# AT32F457xx_v2 register map
Vendor: Keil; Series: AT32F457; File version: 1.0
CPU: CM4 r0p1, little endian, no MPU, FPU, 4 interrupt priority bits
Registers are 32-bit, read-write, reset 0x0 unless marked. A register's access mark holds for its fields unless they carry their own. Offsets are from the block's base; [hi:lo] are bit positions.

## ETHERNET_DMA — Ethernet: DMA controller operation
Base 0x40029000
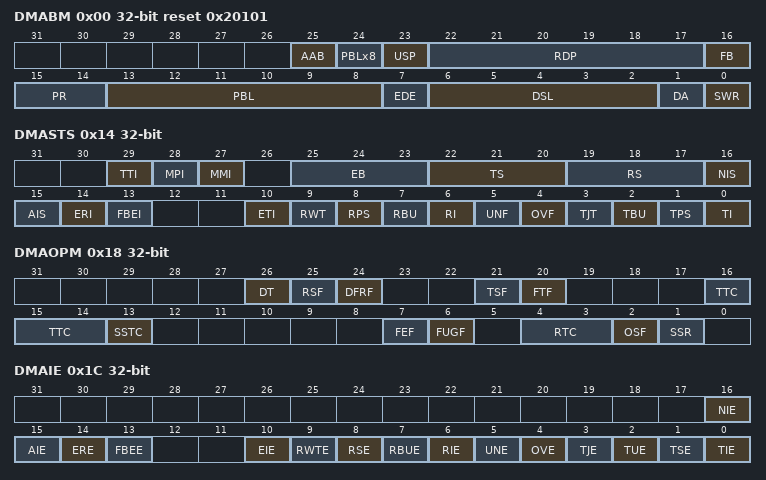
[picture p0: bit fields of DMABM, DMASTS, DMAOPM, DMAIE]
0x00 DMABM reset 0x20101 — Ethernet DMA bus mode register
  [25] AAB — Address-aligned beats
  [24] PBLx8 — PNLx8 mode
  [23] USP — Use separate PBL
  [22:17] RDP — Rx DMA PBL
  [16] FB — Fixed burst
  [15:14] PR — Priority ratio
  [13:8] PBL — Programmable burst length
  [7] EDE — Enhanced descriptor enable
  [6:2] DSL — Descriptor skip length
  [1] DA — DMA Arbitration
  [0] SWR — Software reset
0x04 DMATPD — Ethernet DMA transmit poll demand register
  [31:0] TPD — Transmit poll demand
0x08 DMARPD — EHERNET DMA receive poll demand register
  [31:0] RPD — Receive poll demand
0x0C DMARDLADDR — Ethernet DMA receive descriptor list address register
  [31:0] SRL — Start of receive list
0x10 DMATDLADDR — Ethernet DMA transmit descriptor list address register
  [31:0] STL — Start of transmit list
0x14 DMASTS — Ethernet DMA status register
  [29] TTI ro — Timestamp trigger interrupt
  [28] MPI ro — MAC PMT interrupt
  [27] MMI ro — MAC MMC interrupt
  [25:23] EB ro — Error bits
  [22:20] TS ro — Transmit process state
  [19:17] RS ro — Receive process state
  [16] NIS — Normal interrupt summary
  [15] AIS — Abnormal interrupt summary
  [14] ERI — Early receive interrupt
  [13] FBEI — Fatal bus error interrupt
  [10] ETI — Early transmit interrupt
  [9] RWT — Receive watchdog timeout
  [8] RPS — Receive process stopped
  [7] RBU — Receive buffer unavailable
  [6] RI — Receive interrupt
  [5] UNF — Transmit underflow
  [4] OVF — Receive overflow
  [3] TJT — Transmit jabber timeout
  [2] TBU — Transmit buffer unavailable
  [1] TPS — Transmit process stopped
  [0] TI — Transmit interrupt
0x18 DMAOPM — Ethernet DMA operation mode register
  [26] DT — Disable dropping of TCP/IP checksum error frames
  [25] RSF — Receive store and forward
  [24] DFRF — Disable flushing of received frames
  [21] TSF — Transmit store and forward
  [20] FTF — Flush transmit FIFO
  [16:14] TTC — Transmit threshold control
  [13] SSTC — Start of stop transmission command
  [7] FEF — Forward error frames
  [6] FUGF — Forward undersized good frames
  [4:3] RTC — Receive threshold control
  [2] OSF — Operate on second frame
  [1] SSR — Start or stop receive
0x1C DMAIE — Ethernet DMA interrupt enable register
  [16] NIE — Normal interrupt enable
  [15] AIE — Abnormal interrupt enable
  [14] ERE — Early receive interrupt enable
  [13] FBEE — Fatal bus error enable
  [10] EIE — Early transmit interrupt enable
  [9] RWTE — receive watchdog timeout enable
  [8] RSE — Receive stopped enable
  [7] RBUE — Receive buffer unavailable enable
  [6] RIE — Receive interrupt enable
  [5] UNE — Underflow interrupt enable
  [4] OVE — Overflow interrupt enable
  [3] TJE — Transmit jabber timeout enable
  [2] TUE — Transmit buffer unavailable enable
  [1] TSE — Transmit stopped enable
  [0] TIE — Transmit interrupt enable
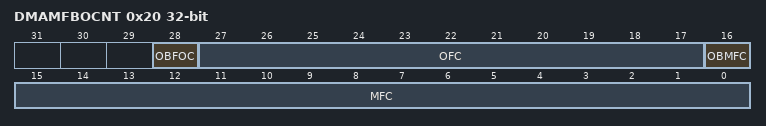
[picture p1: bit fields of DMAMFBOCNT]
0x20 DMAMFBOCNT ro — Ethernet DMA missed frame and buffer overflow counter register
  [28] OBFOC — Overflow bit for FIFO overflow counter
  [27:17] OFC — Overflow frame counter
  [16] OBMFC — Overflow bit for missed frame counter
  [15:0] MFC — Missed frames control
0x48 DMACTD ro — Ethernet DMA current host transmit descriptor register
  [31:0] HTDAP — Host transmit descriptor address pointer
0x4C DMACRD ro — Ethernet DMA current host receive descriptor register
  [31:0] HRDAP — Host receive descriptor address pointer
0x50 DMACTBADDR ro — Ethernet DMA current host transmit buffer address register
  [31:0] HTBAP — Host transmit buffer address pointer
0x54 DMACRBADDR ro — Ethernet DMA current host receive buffer address register
  [31:0] HRBAP — Host receive buffer address pointer
